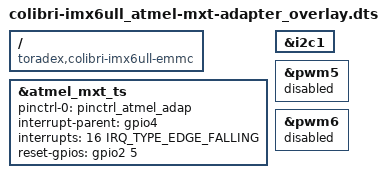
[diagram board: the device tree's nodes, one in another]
// SPDX-License-Identifier: GPL-2.0-or-later OR MIT
/*
 * Copyright 2021 Toradex
 */

// Atmel MXT touchscreen for the 7inch and 10inch display orderable at Toradex.
// Compatible with a Capacitive Touch Adapter.

/dts-v1/;
/plugin/;

#include <dt-bindings/gpio/gpio.h>
#include <dt-bindings/interrupt-controller/irq.h>

/ {
	compatible = "toradex,colibri-imx6ull-emmc";
};

&atmel_mxt_ts {
	pinctrl-0 = <&pinctrl_atmel_adap>;
	interrupt-parent = <&gpio4>;
	interrupts = <16 IRQ_TYPE_EDGE_FALLING>;   /* SODIMM 28, INT */
	reset-gpios = <&gpio2 5 GPIO_ACTIVE_HIGH>; /* SODIMM 30, RST */
	status = "okay";
};

&i2c1 {
	status = "okay";
};

/* PWM <B> */
&pwm5 {
	/* Pin already used by atmel_mxt_ts touchscreen */
	status = "disabled";
};

/* PWM <C> */
&pwm6 {
	/* Pin already used by atmel_mxt_ts touchscreen */
	status = "disabled";
};
